# CM41x_M4 register map
Vendor: Analog Devices; Series: CM41x_M4; File version: 1p0
CPU: CM4 r0p1, little endian, MPU, FPU, 4 interrupt priority bits
Registers are 32-bit, read-write, reset 0x0 unless marked. A register's access mark holds for its fields unless they carry their own. Offsets are from the block's base; [hi:lo] are bit positions; lines under a group give offsets from that group; {n}, {i} and the like mark numbered series.

## SPU1 — System Protection Unit
Base 0x400F8000
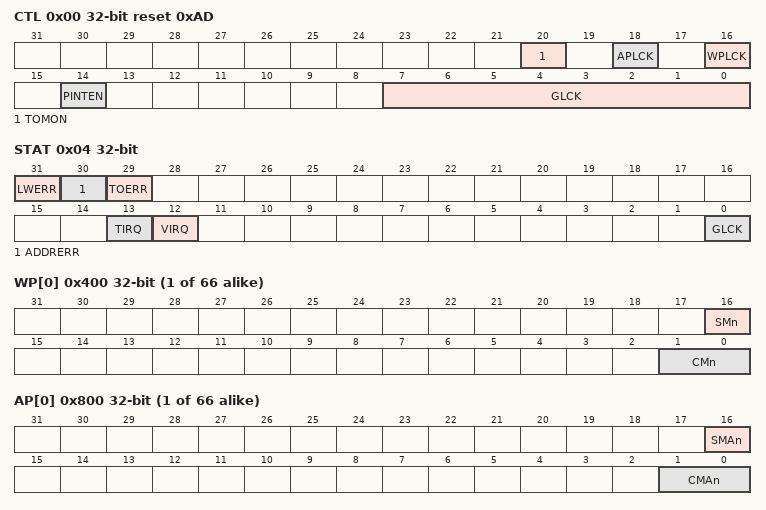
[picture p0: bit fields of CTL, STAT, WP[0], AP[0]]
0x00 CTL reset 0xAD — Control Register
  [20] TOMON — Timeout Monitor
  [18] APLCK — Access Protect Register Lock
  [16] WPLCK — Write Protect Register Lock
  [14] PINTEN — Protection Violation Interrupt Enable
  [7:0] GLCK range 0x00000000..0x000000FF — Global Lock
0x04 STAT — Status Register
  [31] LWERR — Lock Write Error
  [30] ADDRERR — Address Error
  [29] TOERR ro — Timeout Error
  [13] TIRQ — Timeout Interrupt
  [12] VIRQ — Violation Interrupt Request
  [0] GLCK ro — Global Lock Status
0x40 TIMEOUT
  [15:0] VALUE range 0x00000000..0x0000FFFF — Timeout Counter Value
{0x400+4i} WP[{i}] (i=0..65) — Write Protect Register n
  [16] SMn range 0x00000000..0x00000001 — System Master x Write Protect Enable
  [1:0] CMn range 0x00000000..0x00000003 — Core Master x Write Protect Enable
{0x800+4i} AP[{i}] (i=0..65) — Access Protect Register n
  [16] SMAn range 0x00000000..0x00000001 — System Master x Access Protect Enable
  [1:0] CMAn range 0x00000000..0x00000003 — Core Master x Access Protect Enable
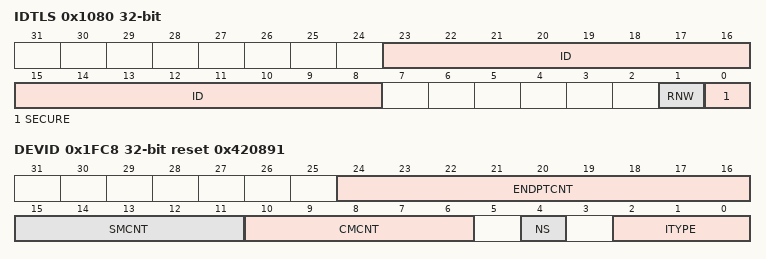
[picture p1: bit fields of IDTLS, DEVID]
0x1080 IDTLS — Interrupt Details Register
  [23:8] ID ro — ID of Transaction
  [1] RNW ro — Read/Write Status
  [0] SECURE ro — Secure Status
0x1084 IADDR — Interrupt Address Register
  [31:0] VALUE ro — Violation Address
0x1FC8 DEVID reset 0x420891 — Device Configuration Register
  [24:16] ENDPTCNT ro — End Point Count
  [15:11] SMCNT ro — System Master Count
  [10:6] CMCNT ro — Core Master Count
  [4] NS ro — No Security
  [2:0] ITYPE ro — Interface Type

## SPU0 — System Protection Unit
Base 0x410F8000
Registers as SPU1, without WP[*], AP[*]; these are added or differ:
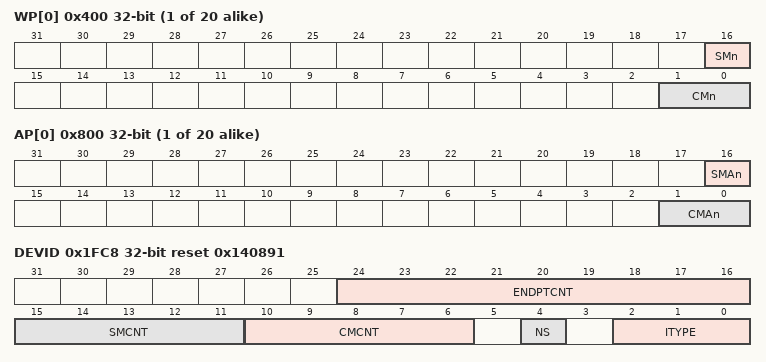
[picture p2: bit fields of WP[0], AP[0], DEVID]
{0x400+4i} WP[{i}] (i=0..19) — Write Protect Register n
  [16] SMn range 0x00000000..0x00000001 — System Master x Write Protect Enable
  [1:0] CMn range 0x00000000..0x00000003 — Core Master x Write Protect Enable
{0x800+4i} AP[{i}] (i=0..19) — Access Protect Register n
  [16] SMAn range 0x00000000..0x00000001 — System Master x Access Protect Enable
  [1:0] CMAn range 0x00000000..0x00000003 — Core Master x Access Protect Enable
0x1FC8 DEVID reset 0x140891 — Device Configuration Register
  [24:16] ENDPTCNT ro — End Point Count
  [15:11] SMCNT ro — System Master Count
  [10:6] CMCNT ro — Core Master Count
  [4] NS ro — No Security
  [2:0] ITYPE ro — Interface Type

## PADS0 — Pads Controller
Base 0x41001000
0x04 PCFG0 — Peripheral Configuration0 Register
  [12] PUE range 0x00000000..0x00000001 — Pull-Up Enable
0x100 PORTA_DS — Multi Port Drive Strength Control Register
  [15:0] GPIO_DS range 0x00000000..0x0000FFFF — Port Drive Strength
0x120 PORTA_RCTL — Multi Port Pull-up/Pull-down Resistor Control Register
  [15:0] REN_CTL range 0x00000000..0x0000FFFF — Port Resistor Enable Control
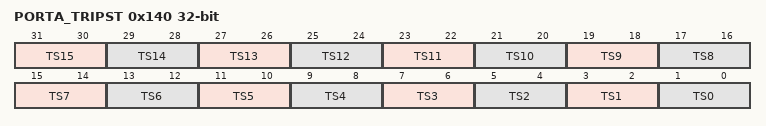
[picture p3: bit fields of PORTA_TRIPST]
0x140 PORTA_TRIPST — Multi Port Trip State Register
  [2n+1:2n] TS{n} range 0x00000000..0x00000003 (n=1..15) — Port IO {n} Trip State
  [1:0] TS0 range 0x00000000..0x00000003 — Port IO_0 Trip State
0x160 PORTA_TRIPSEL — Multi Port Trip Select Register
  [15:0] SEL range 0x00000000..0x0000FFFF — Trip A/B Mux Select

## SMPU0 — The System Memory Protection Unit
Base 0x410E0000
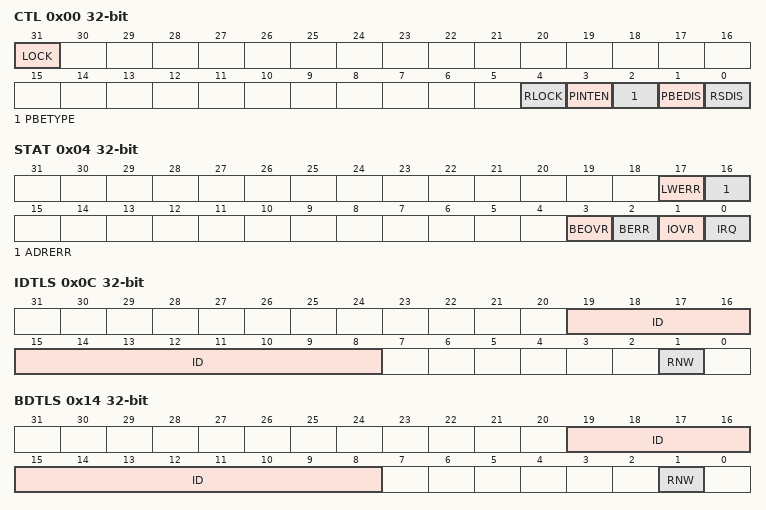
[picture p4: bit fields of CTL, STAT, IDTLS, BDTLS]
0x00 CTL — SMPU Control Register
  [31] LOCK — Lock Bit
  [4] RLOCK — RCTLn, RADDRn, RIDxn and RIDMxn Registers Lock Bit
  [3] PINTEN — Protection Violation Interrupt Enable
    0=PINTDIS (Protection Violation IRQ Disable.); 1=PINTEN (Protection Violation IRQ Enable.)
  [2] PBETYPE — Protection Violation Bus Error Type
    0=DECERR (Decode Error Type.); 1=SLVERR (Save Error Type.)
  [1] PBEDIS — Protection Violation Bus Error Disable
    0=PBEEN (Bus Error Generation Enable.); 1=PBEDIS (Bus Error Generation Disable.)
  [0] RSDIS — Read Speculation Disable
    0=RSEN (Read Speculation Enable.); 1=RSDIS (Read Speculation Disable.)
0x04 STAT — SMPU Status Register
  [17] LWERR — Lock Write Error
    0=NOLWERR (No Lock Write Error); 1=LWERR (Lock Write Error)
  [16] ADRERR — Address Error
    0=NOADRERR (No Address Error); 1=ADRERR (Address Error)
  [3] BEOVR — Bus Error Overrun
    0=NOBEOVR (No Bus Error overrun); 1=BEOVR (Bus Error overrun has occurred)
  [2] BERR — Bus Error
    0=NOBERR (No Bus Error since this bit has been cleared); 1=BERR (Bus Error has been generated)
  [1] IOVR — Interrupt Overrun
    0=NOIOVR (No Interrupt overrun); 1=IOVR (Interrupt overrun has occurred)
  [0] IRQ — Interrupt Request
    0=NOIRQ (No Interrupt since this bit has been cleared); 1=IRQ (Interrupt has been generated)
0x08 IADDR — Interrupt Address Register
  [31:0] VALUE ro — Interrupt Address
0x0C IDTLS — Interrupt Details Register
  [19:8] ID ro — ID of Transaction.
  [1] RNW ro — Read/Write Status.
    0=WRITE (Transaction that caused last signaled interrupt was a write); 1=READ (Transaction that caused last signaled interrupt was a read)
0x10 BADDR — Bus Error Address Register
  [31:0] VALUE ro — Bus Error Address
0x14 BDTLS — Bus Error Details Register
  [19:8] ID ro — ID of Transaction
  [1] RNW ro — Read/Write Status
    0=WRITE (Transaction that caused last bus error was a write); 1=READ (Transaction that caused last bus error was a read)
{0x20+0x18*i} SMPU0_Rn[{i}] (i=0..3) group — Region n
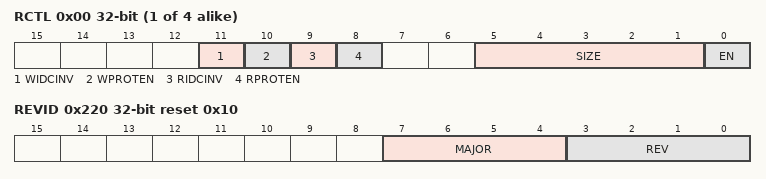
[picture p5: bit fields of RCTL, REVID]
  0x00 RCTL — Region n Control Register
    [11] WIDCINV — Write Transaction ID Compare Invert
    [10] WPROTEN — Write Transaction Protection Enable
      0=WPROTDIS (Write transaction ID-based protection disabled); 1=WPROTEN (Write transaction ID-based protection enabled)
    [9] RIDCINV — Read Transaction ID Compare Invert
    [8] RPROTEN — Read Transaction Protection Enable
      0=RPROTDIS (Read transaction ID-based protection disabled); 1=RPROTEN (Read transaction ID-based protection enabled)
    [5:1] SIZE — Memory Region Size
    [0] EN — Region Enable
  0x04 RADDR — Region n Address Register
    [31:12] BADDR range 0x00000000..0x000FFFFF — Region n Base Address 20 Most Significant Bits
  0x08 RIDA — Region n ID A Register
    [11:0] ID range 0x00000000..0x00000FFF — Region n ID Register A
  0x0C RIDMSKA — Region n ID Mask A Register
    [11:0] MSK range 0x00000000..0x00000FFF — Region n ID Mask Register A
  0x10 RIDB — Region n ID B Register
    [11:0] ID range 0x00000000..0x00000FFF — Region n ID Register B
  0x14 RIDMSKB — Region n ID Mask B Register
    [11:0] MSK range 0x00000000..0x00000FFF — Region n ID Mask Register B
0x220 REVID reset 0x10 — SMPU Revision ID Register
  [7:4] MAJOR ro — Major Version ID
  [3:0] REV ro — Incremental Version ID
